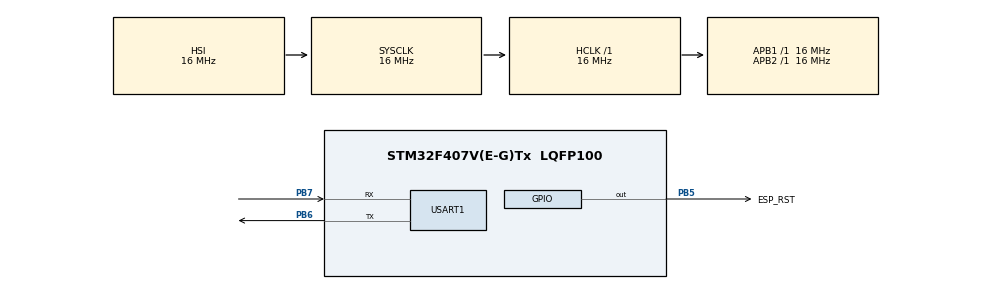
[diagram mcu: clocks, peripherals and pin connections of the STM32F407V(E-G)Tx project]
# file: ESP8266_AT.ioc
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FREERTOS.Tasks01=WiFi,16,128,WiFi_Task,As weak,NULL,Dynamic,NULL,NULL;LED,14,128,Led_Task,As weak,NULL,Dynamic,NULL,NULL
FREERTOS.configUSE_NEWLIB_REENTRANT=1
Mcu.Family=STM32F4
Mcu.Name=STM32F407V(E-G)Tx
Mcu.Package=LQFP100
NVIC.PriorityGroup=NVIC_PRIORITYGROUP_4
NVIC.TIM6_DAC_IRQn=true\:15\:0\:false\:false\:true\:false\:true\:true\:true
NVIC.TimeBase=TIM6_DAC_IRQn
NVIC.TimeBaseIP=TIM6
NVIC.USART1_IRQn=true\:5\:0\:false\:false\:true\:true\:true\:true\:true
PB5.GPIO_Label=ESP_RST
PB5.Signal=GPIO_Output
PB6.Mode=Asynchronous
PB6.Signal=USART1_TX
PB7.Mode=Asynchronous
PB7.Signal=USART1_RX
ProjectManager.HeapSize=0x200
ProjectManager.StackSize=0x400
ProjectManager.TargetToolchain=STM32CubeIDE
RCC.AHBFreq_Value=16000000
RCC.APB1Freq_Value=16000000
RCC.APB2Freq_Value=16000000
RCC.CortexFreq_Value=16000000
RCC.HSE_VALUE=25000000
RCC.HSI_VALUE=16000000
RCC.LSE_VALUE=32768
RCC.SYSCLKFreq_VALUE=16000000
RCC.VCOOutputFreq_Value=192000000
USART1.VirtualMode=VM_ASYNC
VP_FREERTOS_VS_CMSIS_V2.Mode=CMSIS_V2
VP_SYS_VS_tim6.Mode=TIM6
board=custom

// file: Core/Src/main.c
/* USER CODE BEGIN Header */
/**
  ******************************************************************************
  * @file           : main.c
  * @brief          : Main program body
  ******************************************************************************
  * @attention
  *
  * Copyright (c) 2023 STMicroelectronics.
  * All rights reserved.
  *
  * This software is licensed under terms that can be found in the LICENSE file
  * in the root directory of this software component.
  * If no LICENSE file comes with this software, it is provided AS-IS.
  *
  ******************************************************************************
  */
/* USER CODE END Header */
#include "main.h"
#include "cmsis_os.h"
#include "usart.h"
#include "gpio.h"

/* USER CODE BEGIN Includes */
#include "esp8266.h"
#include <stdio.h>
/* USER CODE END Includes */

void SystemClock_Config(void);
void MX_FREERTOS_Init(void);

/* USER CODE BEGIN 0 */
extern ESP8266_t ESP8266;
/* USER CODE END 0 */

int main(void)
{

  /* MCU Configuration--------------------------------------------------------*/

  /* Reset of all peripherals, Initializes the Flash interface and the Systick. */
  HAL_Init();

  /* Configure the system clock */
  SystemClock_Config();

  /* Initialize all configured peripherals */
  MX_GPIO_Init();
  MX_USART1_UART_Init();

  /* Init scheduler */
  osKernelInitialize();  /* Call init function for freertos objects (in freertos.c) */
  MX_FREERTOS_Init();

  /* Start scheduler */
  osKernelStart();
  /* We should never get here as control is now taken by the scheduler */
  /* Infinite loop */
  while (1)
  {

  }
}

void SystemClock_Config(void)
{
  RCC_OscInitTypeDef RCC_OscInitStruct = {0};
  RCC_ClkInitTypeDef RCC_ClkInitStruct = {0};

  /** Configure the main internal regulator output voltage
  */
  __HAL_RCC_PWR_CLK_ENABLE();
  __HAL_PWR_VOLTAGESCALING_CONFIG(PWR_REGULATOR_VOLTAGE_SCALE1);

  /** Initializes the RCC Oscillators according to the specified parameters
  * in the RCC_OscInitTypeDef structure.
  */
  RCC_OscInitStruct.OscillatorType = RCC_OSCILLATORTYPE_HSI;
  RCC_OscInitStruct.HSIState = RCC_HSI_ON;
  RCC_OscInitStruct.HSICalibrationValue = RCC_HSICALIBRATION_DEFAULT;
  RCC_OscInitStruct.PLL.PLLState = RCC_PLL_NONE;
  if (HAL_RCC_OscConfig(&RCC_OscInitStruct) != HAL_OK)
  {
    Error_Handler();
  }

  /** Initializes the CPU, AHB and APB buses clocks
  */
  RCC_ClkInitStruct.ClockType = RCC_CLOCKTYPE_HCLK|RCC_CLOCKTYPE_SYSCLK
                              |RCC_CLOCKTYPE_PCLK1|RCC_CLOCKTYPE_PCLK2;
  RCC_ClkInitStruct.SYSCLKSource = RCC_SYSCLKSOURCE_HSI;
  RCC_ClkInitStruct.AHBCLKDivider = RCC_SYSCLK_DIV1;
  RCC_ClkInitStruct.APB1CLKDivider = RCC_HCLK_DIV1;
  RCC_ClkInitStruct.APB2CLKDivider = RCC_HCLK_DIV1;

  if (HAL_RCC_ClockConfig(&RCC_ClkInitStruct, FLASH_LATENCY_0) != HAL_OK)
  {
    Error_Handler();
  }
}

/* USER CODE BEGIN 4 */

void Led_Task(void *argument)
{
  /* USER CODE BEGIN Led_Task */
	osDelay(15000);
	ESP8266_StartClientConnectionTCP(&ESP8266, "MQTT", "192.168.1.38", 1883, NULL);
	//ESP8266_RequestSendData(&ESP8266, Connection);
	/* Infinite loop */
  for(;;)
  {

    osDelay(1);
  }
  /* USER CODE END Led_Task */
}
void ESP8266_Callback_ClientConnectionConnected(ESP8266_t* ESP8266, ESP8266_Connection_t* Connection) {
    /* NOTE: This function Should not be modified, when the callback is needed,
           the ESP8266_Callback_ClientConnectionConnected could be implemented in the user file
    */
	printf("conexion al servidor exitosa\r\n");
	ESP8266_CloseConnection(ESP8266, Connection);
}

void ESP8266_Callback_ClientConnectionError(ESP8266_t* ESP8266, ESP8266_Connection_t* Connection) {
    /* NOTE: This function Should not be modified, when the callback is needed,
           the ESP8266_Callback_ClientConnectionError could be implemented in the user file
    */
	printf("error al tratar de conectarse al servidor\r\n");
}
/* USER CODE END 4 */

void HAL_TIM_PeriodElapsedCallback(TIM_HandleTypeDef *htim)
{
  if (htim->Instance == TIM6) {
    HAL_IncTick();
  }
  /* USER CODE BEGIN Callback 1 */
  ESP8266_TimeUpdate(&ESP8266, 1);
  /* USER CODE END Callback 1 */
}

void Error_Handler(void)
{
  __disable_irq();
  while (1)
  {
  }
}

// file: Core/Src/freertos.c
/* USER CODE BEGIN Header */
/**
  ******************************************************************************
  * File Name          : freertos.c
  * Description        : Code for freertos applications
  ******************************************************************************
  * @attention
  *
  * Copyright (c) 2023 STMicroelectronics.
  * All rights reserved.
  *
  * This software is licensed under terms that can be found in the LICENSE file
  * in the root directory of this software component.
  * If no LICENSE file comes with this software, it is provided AS-IS.
  *
  ******************************************************************************
  */
/* USER CODE END Header */

#include "FreeRTOS.h"
#include "task.h"
#include "main.h"
#include "cmsis_os.h"

/* Definitions for WiFi */
osThreadId_t WiFiHandle;
const osThreadAttr_t WiFi_attributes = {
  .name = "WiFi",
  .stack_size = 128 * 4,
  .priority = (osPriority_t) osPriorityBelowNormal,
};
/* Definitions for LED */
osThreadId_t LEDHandle;
const osThreadAttr_t LED_attributes = {
  .name = "LED",
  .stack_size = 128 * 4,
  .priority = (osPriority_t) osPriorityLow6,
};

void WiFi_Task(void *argument);
void Led_Task(void *argument);

void MX_FREERTOS_Init(void); /* (MISRA C 2004 rule 8.1) */

void MX_FREERTOS_Init(void) {

  /* Create the thread(s) */
  /* creation of WiFi */
  WiFiHandle = osThreadNew(WiFi_Task, NULL, &WiFi_attributes);

  /* creation of LED */
  LEDHandle = osThreadNew(Led_Task, NULL, &LED_attributes);

}

__weak void WiFi_Task(void *argument)
{
  for(;;)
  {
    osDelay(1);
  }
}

__weak void Led_Task(void *argument)
{
  for(;;)
  {
    osDelay(1);
  }
}
